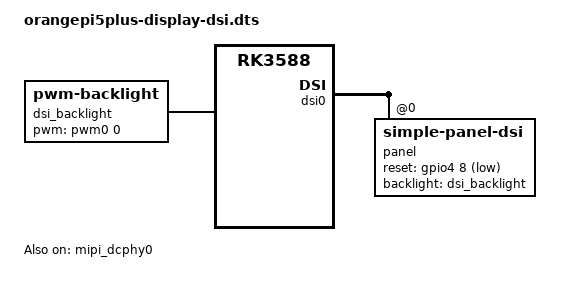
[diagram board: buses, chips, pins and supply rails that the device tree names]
/*
 * Device Tree Overlay: MIPI DSI Panel on Orange Pi 5 Plus
 *
 * Example overlay for a generic MIPI DSI panel. The Orange Pi 5 Plus
 * has two 4-lane MIPI DSI connectors (DSI0 and DSI1), compared to
 * one on the Rock 5T.
 *
 * This template targets DSI0 via mipi_dcphy0. For DSI1, use
 * mipi_dcphy1 instead.
 *
 * IMPORTANT: You MUST customize the panel-init-sequence, timings,
 * and dimensions for your specific panel. The values below are
 * placeholders for a hypothetical 800x480 panel.
 *
 * To compile:
 *   dtc -@ -I dts -O dtb -o orangepi5plus-display-dsi.dtbo orangepi5plus-display-dsi.dts
 */

/dts-v1/;
/plugin/;

/ {
	compatible = "xunlong,orangepi-5-plus", "rockchip,rk3588";

	/* Backlight controlled via PWM */
	fragment@0 {
		target-path = "/";
		__overlay__ {
			dsi_backlight: dsi-backlight {
				compatible = "pwm-backlight";
				/* Adjust PWM channel and period for your board */
				pwms = <&pwm0 0 25000 0>;
				brightness-levels = <
					0  16  32  48  64  80  96  112
					128 144 160 176 192 208 224 240 255
				>;
				default-brightness-level = <12>;
			};
		};
	};

	/* Enable MIPI DC-PHY (combined DSI/CSI PHY on RK3588) */
	fragment@1 {
		target = <&mipi_dcphy0>;
		__overlay__ {
			status = "okay";
		};
	};

	/* Enable DSI0 controller and attach panel */
	fragment@2 {
		target = <&dsi0>;
		__overlay__ {
			status = "okay";
			#address-cells = <1>;
			#size-cells = <0>;

			panel@0 {
				compatible = "simple-panel-dsi";
				reg = <0>;
				backlight = <&dsi_backlight>;
				/* Adjust reset GPIO for OPi5+ */
				reset-gpios = <&gpio4 8 1>; /* GPIO4_B0, active low */

				prepare-delay-ms = <120>;
				reset-delay-ms = <20>;
				init-delay-ms = <100>;
				enable-delay-ms = <100>;

				dsi,flags = <0x3>;     /* MIPI_DSI_MODE_VIDEO | MIPI_DSI_MODE_VIDEO_BURST */
				dsi,format = <0>;      /* MIPI_DSI_FMT_RGB888 */
				dsi,lanes = <4>;

				display-timings {
					native-mode = <&timing0>;

					timing0: timing0 {
						/* 800x480 @ 60Hz — replace with your panel specs */
						clock-frequency = <27000000>;
						hactive = <800>;
						vactive = <480>;
						hfront-porch = <40>;
						hsync-len = <48>;
						hback-porch = <40>;
						vfront-porch = <13>;
						vsync-len = <3>;
						vback-porch = <29>;
						hsync-active = <0>;
						vsync-active = <0>;
						de-active = <0>;
						pixelclk-active = <0>;
					};
				};
			};
		};
	};
};
